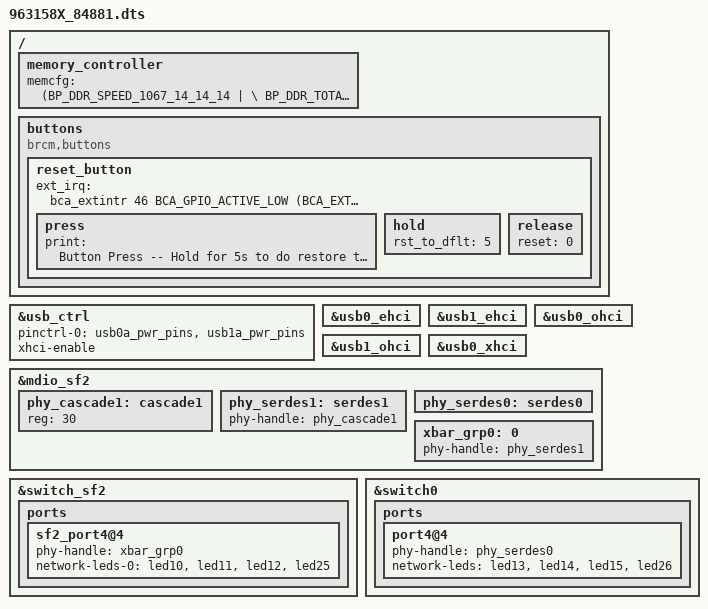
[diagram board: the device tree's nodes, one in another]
#include "63158.dtsi"
#include "963158X_leds.dtsi"

/ {
    memory_controller {
        memcfg = <(BP_DDR_SPEED_1067_14_14_14 | \
                   BP_DDR_TOTAL_SIZE_512MB    | \
                   BP_DDR_DEVICE_WIDTH_16     | \
                   BP_DDR_TOTAL_WIDTH_16BIT   | \
                   BP_DDR_SSC_CONFIG_1)>;
    };

	buttons {
		compatible = "brcm,buttons";
		reset_button {
			ext_irq = <&bca_extintr 46 BCA_GPIO_ACTIVE_LOW (BCA_EXTINTR_TYPE_LOW_LEVEL | BCA_EXTINTR_TYPE_SENSE_EDGE)>;
			press {
				print = "Button Press -- Hold for 5s to do restore to default";
			};
			hold {
				rst_to_dflt = <5>;
			};
			release {
				reset = <0>;
			};	
		};
	};
};

&usb_ctrl {
	pinctrl-names="default";
	pinctrl-0 = <&usb0a_pwr_pins &usb1a_pwr_pins>;
	status = "okay";
	xhci-enable;
};

&usb0_ehci {
	status = "okay";
};
&usb1_ehci {
	status = "okay";
};

&usb0_ohci {
	status = "okay";
};
&usb1_ohci {
	status = "okay";
};

&usb0_xhci {
	status = "okay";
};

&mdio_sf2 {
	/* Cascade PHY */
	phy_cascade1:cascade1 {
		reg = <30>;
		status = "okay";
	};
	
	/* PHYs connected to crossbar */
	phy_serdes1:serdes1 {
		phy-handle = <&phy_cascade1>;
		status = "okay";
	};

	/* PHY directly connected to Runner */
	phy_serdes0:serdes0 {
		status = "okay";
	};

	/* Crossbar groups */
	xbar_grp0:0 {
		phy-handle = <&phy_serdes1>;
		status = "okay";
	};
};

&switch_sf2 {
	ports {

		sf2_port4@4 {
			phy-handle = <&xbar_grp0>;
			/* xbar ext ep 0 serdes leds */
			network-leds-0 = <&led10 &led11 &led12 &led25>;
			status = "okay";
		};
	};
};

&switch0 {
	ports {
		
		port4@4 {
			phy-handle = <&phy_serdes0>;
			network-leds = <&led13 &led14 &led15 &led26>;
			status = "okay";
		};
	};
};
